# headsail register map
Vendor: tuni.fi; File version: 1.1
CPU: other r1p0, little endian, no MPU, no FPU, vendor SysTick, 2 interrupt priority bits
Registers are 32-bit, read-write, no defined reset value unless marked. A register's access mark holds for its fields unless they carry their own. Offsets are from the block's base; [hi:lo] are bit positions; lines under a group give offsets from that group; {n}, {i} and the like mark numbered series; 'fields as' and 'values as' point back to an identical list.

## DSP — Stores different status information about the core
Base 0x1FF800000
0x00 status group
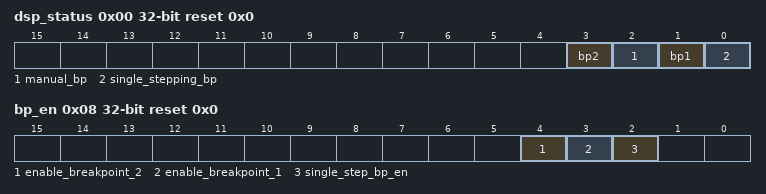
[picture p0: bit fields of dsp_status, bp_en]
  0x00 dsp_status ro reset 0x0 — Status: Shows why the TTA core is in a break state Bit 0: single-stepping breakpoint Bit 1: Breakpoint 1 Bit 2: Breakpoint 2 Bit 3: Manual breakpoint
    [3] bp2, [2] manual_bp, [1] bp1, [0] single_stepping_bp
  0x04 pc ro reset 0x0 — Program counter
  0x08 cycle_count_lo ro reset 0x0 — Low part of Cycle count register
    [31:0] lo — Cycle count (low 32 bits)
  0x0C cycle_count_hi ro reset 0x0 — High part of Cycle count register
    [31:0] hi — Cycle count (high 32 bits)
  0x10 stall_count_lo ro reset 0x0 — Low part of Stall count
    [31:0] lo — Stall count (low 32 bits)
  0x14 stall_count_hi ro reset 0x0 — High part of Stall count
0x40 bus_trace group
  {0x0+4j} bus_trace{j} ro reset 0x0 (j=0..3)
    [31:0] bus_trace
  0x10 bus_trace4 ro
    [31:0] bus_trace
0x200 ctrl group
  0x00 cmd wo reset 0x0 — Command (1 = reset, 2 = run, 4 = break)
  0x04 start_addr reset 0x0
    [31:0] addr — star
  0x08 bp_en reset 0x0 — Breakpoint enable Bit 0-1: Reserved Bit 2: Enable single-stepping breakpoint Bit 3: Enable breakpoint 1 Bit 3: Enable breakpoint 2
    [4] enable_breakpoint_2, [3] enable_breakpoint_1, [2] single_step_bp_en
  0x0C cycle_count_bp access not given — Cycle count breakpoint
  0x10 bp2_addr reset 0x0 — Breakpoint 2 address
  0x14 bp1_addr reset 0x0 — Breakpoint 1 address
0x300 processor_info group
  0x00 device_class ro reset 0x774 — Device class (0x774)
  0x08 interface_version ro reset 0x0 — Interface version (0x3)
  0x0C core_count ro reset 0x1
  0x10 ctrl_size ro reset 0x400 — CTRL size, per core, in bytes
  0x14 instr_mem_size ro reset 0x10000 — Instruction memory size, in bytes
  0x18 instr_mem_start_lo ro reset 0xFF810000 — Start of instruction memory, low 32 bits
    [31:0] start_lo
  0x1C instr_mem_start_hi ro reset 0x0 — Start of instruction memory, high 32-bits
    [31:0] start_hi
  0x20 cq_mem_size_lo ro reset 0x100 — CQ memory size, low 32 bits
    [31:0] size_lo
  0x24 cq_mem_size_hi ro reset 0x0 — CQ memory size, high 32 bits
    [31:0] size_hi
  0x28 cq_mem_start_lo ro reset 0xFF83FF00 — CQ memory start, low 32 bits
    [31:0] start_lo
  0x2C cq_mem_start_hi ro reset 0x0 — CQ memory start, high 32 bits
    [31:0] start_hi
  0x30 data_mem_size_lo ro reset 0xFF00 — Data memory size in bytes, low 32 bits
    [31:0] size_lo
  0x34 data_mem_size_hi ro reset 0x0 — Data memory size in bytes, high 32 bits
    [31:0] size_hi
  0x38 data_mem_start_lo ro reset 0xFF830000 — Data memory start, low 32 bits
    [31:0] start_lo
  0x3C data_mem_start_hi ro reset 0x0 — Data memory start, high 32 bits
    [31:0] start_hi
  0x40 feature_flags_lo ro reset 0x1 — Feature flags, low 32 bits
  0x44 feature_flags_hi ro reset 0x0 — Feature flags, high 32 bits
  0x48 ptr_size ro reset 0x4 — Pointer size
  0x4C debug_feature_support ro reset 0x1 — Debug feature support (0x1)
  0x50 bp_count ro reset 0x2 — Breakpoint count (0x2)

## EthSSPadConf
Base 0x1FF400000
0x00 padCfg group
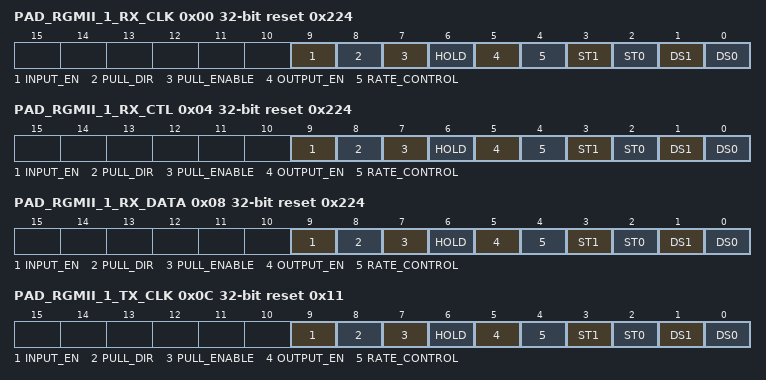
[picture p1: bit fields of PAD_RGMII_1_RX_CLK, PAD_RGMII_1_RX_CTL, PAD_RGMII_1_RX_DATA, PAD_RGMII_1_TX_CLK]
  0x00 PAD_RGMII_1_RX_CLK reset 0x224
    [9] INPUT_EN
      1=enable_input; 0=disable_input
    [8] PULL_DIR
      1=pull_up; 0=pull_down
    [7] PULL_ENABLE
      1=enable_pull; 0=disable_pull
    [6] HOLD
      1=disable_pad; 0=enable_pad
    [5] OUTPUT_EN
      1=disable_output; 0=enable_output
    [4] RATE_CONTROL
      1=enable; 0=disable
    [3] ST1
      1=enable; 0=disable
    [2] ST0
      0=disable; 1=enable
    [1] DS1
      1=enable; 0=disable
    [0] DS0
      1=enable; 0=disable
  0x04 PAD_RGMII_1_RX_CTL reset 0x224
    fields as padCfg.PAD_RGMII_1_RX_CLK
  0x08 PAD_RGMII_1_RX_DATA reset 0x224
    fields as padCfg.PAD_RGMII_1_RX_CLK
  0x0C PAD_RGMII_1_TX_CLK reset 0x11
    fields as padCfg.PAD_RGMII_1_RX_CLK
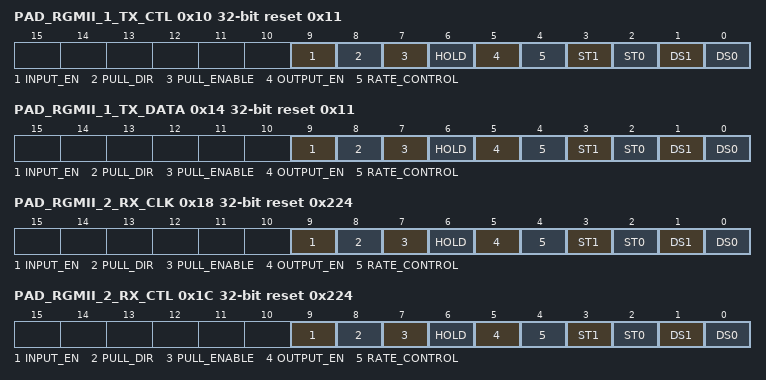
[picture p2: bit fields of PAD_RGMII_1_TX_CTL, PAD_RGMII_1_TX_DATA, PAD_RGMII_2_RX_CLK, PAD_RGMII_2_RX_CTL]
  0x10 PAD_RGMII_1_TX_CTL reset 0x11
    fields as padCfg.PAD_RGMII_1_RX_CLK
  0x14 PAD_RGMII_1_TX_DATA reset 0x11
    fields as padCfg.PAD_RGMII_1_RX_CLK
  0x18 PAD_RGMII_2_RX_CLK reset 0x224
    fields as padCfg.PAD_RGMII_1_RX_CLK
  0x1C PAD_RGMII_2_RX_CTL reset 0x224
    fields as padCfg.PAD_RGMII_1_RX_CLK
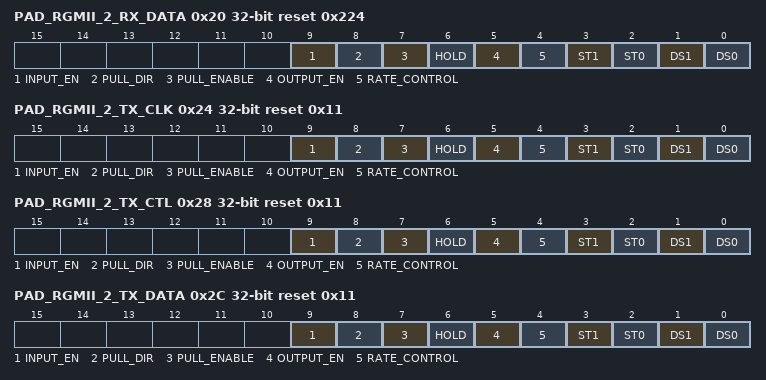
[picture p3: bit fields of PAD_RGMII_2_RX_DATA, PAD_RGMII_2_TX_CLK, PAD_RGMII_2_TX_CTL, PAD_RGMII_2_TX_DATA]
  0x20 PAD_RGMII_2_RX_DATA reset 0x224
    fields as padCfg.PAD_RGMII_1_RX_CLK
  0x24 PAD_RGMII_2_TX_CLK reset 0x11
    fields as padCfg.PAD_RGMII_1_RX_CLK
  0x28 PAD_RGMII_2_TX_CTL reset 0x11
    fields as padCfg.PAD_RGMII_1_RX_CLK
  0x2C PAD_RGMII_2_TX_DATA reset 0x11
    fields as padCfg.PAD_RGMII_1_RX_CLK
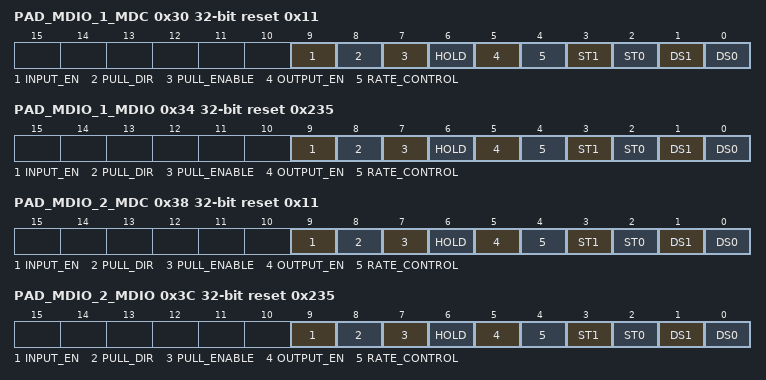
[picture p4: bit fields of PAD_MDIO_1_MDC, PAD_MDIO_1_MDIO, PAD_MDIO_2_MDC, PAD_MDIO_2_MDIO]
  0x30 PAD_MDIO_1_MDC reset 0x11
    fields as padCfg.PAD_RGMII_1_RX_CLK
  0x34 PAD_MDIO_1_MDIO reset 0x235
    [9] INPUT_EN ro
      1=enable_input; 0=disable_input
    [8] PULL_DIR
      1=pull_up; 0=pull_down
    [7] PULL_ENABLE
      1=enable_pull; 0=disable_pull
    [6] HOLD
      1=disable_pad; 0=enable_pad
    [5] OUTPUT_EN ro
      1=disable_output; 0=enable_output
    [4] RATE_CONTROL
      1=enable; 0=disable
    [3] ST1
      1=enable; 0=disable
    [2] ST0
      0=disable; 1=enable
    [1] DS1
      1=enable; 0=disable
    [0] DS0
      1=enable; 0=disable
  0x38 PAD_MDIO_2_MDC reset 0x11
    fields as padCfg.PAD_RGMII_1_RX_CLK
  0x3C PAD_MDIO_2_MDIO reset 0x235
    fields as padCfg.PAD_MDIO_1_MDIO
  0x40 RGMII_SEL reset 0x0
    [0] RGMII_SEL
      0=SEL_TSN_IP; 1=SEL_ETH_IP
